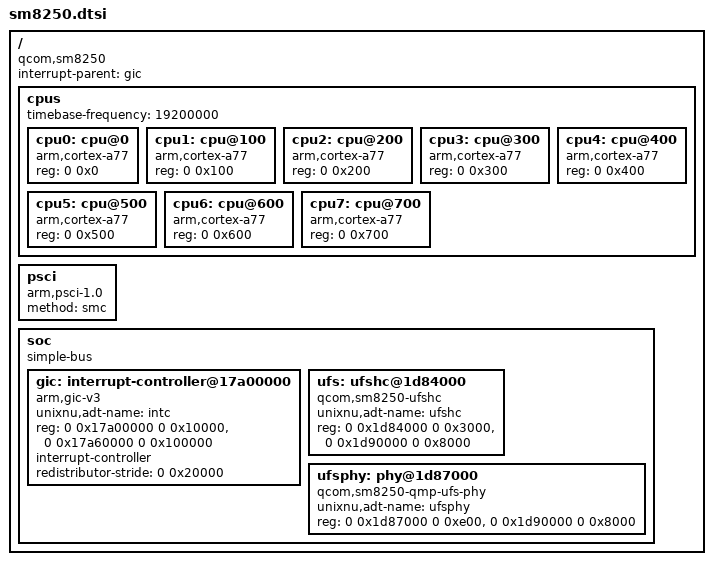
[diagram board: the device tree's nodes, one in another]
// SPDX-License-Identifier: BSD-3-Clause
// Qualcomm SM8250 (kona) shared resources.
//
// Register ranges, interrupt numbers and the timer rate come from the device's own
// kernel tree: arch/arm64/boot/dts/vendor/qcom/kona.dtsi.
//
// What this file describes is the subset UniXNU's ArmDTPlatform and ArmCpu need:
// CPU topology, the GICv3 distributor/redistributor window, the architected timer and
// the UFS host/PHY. Peripherals stay out until a driver consumes them.
/ {
    compatible = "qcom,sm8250";
    #address-cells = <2>;
    #size-cells = <2>;
    interrupt-parent = <&gic>;

    cpus {
        #address-cells = <2>;
        #size-cells = <0>;
        timebase-frequency = <19200000>;

        cpu0: cpu@0 { device_type = "cpu"; compatible = "arm,cortex-a77"; reg = <0 0x0>; };
        cpu1: cpu@100 { device_type = "cpu"; compatible = "arm,cortex-a77"; reg = <0 0x100>; };
        cpu2: cpu@200 { device_type = "cpu"; compatible = "arm,cortex-a77"; reg = <0 0x200>; };
        cpu3: cpu@300 { device_type = "cpu"; compatible = "arm,cortex-a77"; reg = <0 0x300>; };
        cpu4: cpu@400 { device_type = "cpu"; compatible = "arm,cortex-a77"; reg = <0 0x400>; };
        cpu5: cpu@500 { device_type = "cpu"; compatible = "arm,cortex-a77"; reg = <0 0x500>; };
        cpu6: cpu@600 { device_type = "cpu"; compatible = "arm,cortex-a77"; reg = <0 0x600>; };
        cpu7: cpu@700 { device_type = "cpu"; compatible = "arm,cortex-a77"; reg = <0 0x700>; };
    };

    psci {
        compatible = "arm,psci-1.0";
        method = "smc";
    };

    soc {
        compatible = "simple-bus";
        #address-cells = <2>;
        #size-cells = <2>;
        ranges;

        // GICv3: distributor at 0x17a00000, eight redistributor frames at 0x17a60000.
        // kona declares three interrupt cells, so specifiers are <type number flags>.
        gic: interrupt-controller@17a00000 {
            compatible = "arm,gic-v3";
            unixnu,adt-name = "intc";
            reg = <0 0x17a00000 0 0x10000>, <0 0x17a60000 0 0x100000>;
            #interrupt-cells = <3>;
            #address-cells = <0>;
            interrupt-controller;
            redistributor-stride = <0 0x20000>;
        };

        // UFS 3.0 host controller. The second range is the inline crypto engine,
        // which kona folds into the same node.
        ufs: ufshc@1d84000 {
            compatible = "qcom,sm8250-ufshc";
            unixnu,adt-name = "ufshc";
            reg = <0 0x1d84000 0 0x3000>, <0 0x1d90000 0 0x8000>;
            reg-names = "ufs_mem", "ufs_ice";
            // No interrupts on purpose: the driver polls completion, and a specifier here
            // makes IODTMapInterruptsSharing dereference a NULL parent (hardware panicked in
            // IODTGetICellCounts before this line was commented out).
            // interrupts = <0 265 4>;
            status = "okay";
        };

        ufsphy: phy@1d87000 {
            compatible = "qcom,sm8250-qmp-ufs-phy";
            unixnu,adt-name = "ufsphy";
            reg = <0 0x1d87000 0 0xe00>, <0 0x1d90000 0 0x8000>;
            reg-names = "phy_mem", "ufs_ice";
            status = "okay";
        };
    };
};
